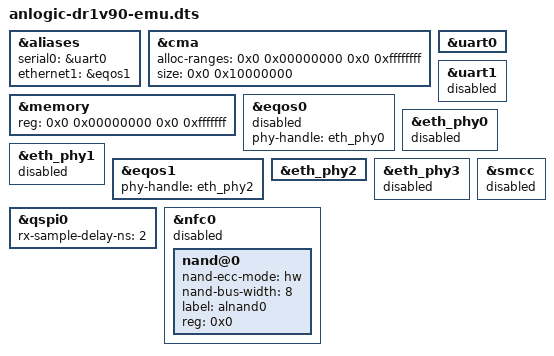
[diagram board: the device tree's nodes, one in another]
// SPDX-License-Identifier: (GPL-2.0+ OR MIT)

/dts-v1/;
#include "anlogic-dr1v90.dts"

&aliases {
	serial0 = &uart0;
	ethernet1 = &eqos1;
};

&cma {
	alloc-ranges = <0x0 0x00000000 0x0 0xffffffff>;
	size = <0x0 0x10000000>;
};

&memory {
	reg = <0x0 0x00000000 0x0 0xfffffff>;
};

&uart0 {
	status = "okay";
};

&uart1 {
	status = "disabled";
};

&eqos0 {
	phy-handle = <&eth_phy0>;
	status = "disabled";
};

&eth_phy0 {
	/* Realtek RTL8211F (0x001cc916) */
	status = "disabled";
};

&eth_phy1 {
	/* Motorcomm YT8531 (0x4f51e91b) */
	status = "disabled";
};

&eqos1 {
	phy-handle = <&eth_phy2>;
	status = "okay";
};

&eth_phy2 {
	/* Realtek RTL8211F (0x001cc916) */
	status = "okay";
};

&eth_phy3 {
	/* Motorcomm YT8531 (0x4f51e91b) */
	status = "disabled";
};

&qspi0 {
	rx-sample-delay-ns = <2>;
	status = "okay";
};

&smcc {
	status = "disabled";
};

&nfc0 {
	status = "disabled";
	#address-cells = <1>;
	#size-cells = <0>;

	nand@0 {
		nand-ecc-mode = "hw";
		nand-bus-width = <8>;
		label = "alnand0";
		reg = <0x0>;
	};
};
